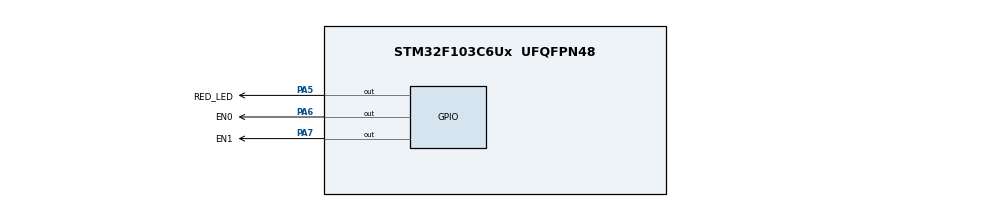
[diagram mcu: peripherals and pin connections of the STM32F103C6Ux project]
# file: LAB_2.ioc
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Mcu.Family=STM32F1
Mcu.Name=STM32F103C6Ux
Mcu.Package=UFQFPN48
NVIC.PriorityGroup=NVIC_PRIORITYGROUP_4
NVIC.TIM2_IRQn=true\:0\:0\:false\:false\:true\:true\:true
PA5.GPIO_Label=RED_LED
PA5.Signal=GPIO_Output
PA6.GPIO_Label=EN0
PA6.Signal=GPIO_Output
PA7.GPIO_Label=EN1
PA7.Signal=GPIO_Output
ProjectManager.HeapSize=0x200
ProjectManager.StackSize=0x400
ProjectManager.TargetToolchain=STM32CubeIDE
RCC.APB1Freq_Value=8000000
RCC.APB2Freq_Value=8000000
TIM2.Period=9
TIM2.Prescaler=7999
VP_SYS_VS_ND.Mode=No_Debug
VP_TIM2_VS_ClockSourceINT.Mode=Internal
board=custom

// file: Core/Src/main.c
/* USER CODE BEGIN Header */
/**
  ******************************************************************************
  * @file           : main.c
  * @brief          : Main program body
  ******************************************************************************
  * @attention
  *
  * <h2><center>&copy; Copyright (c) 2025 STMicroelectronics.
  * All rights reserved.</center></h2>
  *
  * This software component is licensed by ST under BSD 3-Clause license,
  * the "License"; You may not use this file except in compliance with the
  * License. You may obtain a copy of the License at:
  *                        opensource.org/licenses/BSD-3-Clause
  *
  ******************************************************************************
  */
/* USER CODE END Header */
#include "main.h"

/* USER CODE BEGIN Includes */
#include "software_timer.h"
/* USER CODE END Includes */

TIM_HandleTypeDef htim2;

void SystemClock_Config(void);
static void MX_GPIO_Init(void);
static void MX_TIM2_Init(void);

void display7SEG(int num){
	switch(num){
	case 0:
		HAL_GPIO_WritePin(GPIOB, SEG_a, GPIO_PIN_RESET);
		HAL_GPIO_WritePin(GPIOB, SEG_b, GPIO_PIN_RESET);
		HAL_GPIO_WritePin(GPIOB, SEG_c, GPIO_PIN_RESET);
		HAL_GPIO_WritePin(GPIOB, SEG_d, GPIO_PIN_RESET);
		HAL_GPIO_WritePin(GPIOB, SEG_e, GPIO_PIN_RESET);
		HAL_GPIO_WritePin(GPIOB, SEG_f, GPIO_PIN_RESET);
		HAL_GPIO_WritePin(GPIOB, SEG_g, GPIO_PIN_SET);
		break;
	case 1:
		HAL_GPIO_WritePin(GPIOB, SEG_a, GPIO_PIN_SET);
		HAL_GPIO_WritePin(GPIOB, SEG_b, GPIO_PIN_RESET);
		HAL_GPIO_WritePin(GPIOB, SEG_c, GPIO_PIN_RESET);
		HAL_GPIO_WritePin(GPIOB, SEG_d, GPIO_PIN_SET);
		HAL_GPIO_WritePin(GPIOB, SEG_e, GPIO_PIN_SET);
		HAL_GPIO_WritePin(GPIOB, SEG_f, GPIO_PIN_SET);
		HAL_GPIO_WritePin(GPIOB, SEG_g, GPIO_PIN_SET);
		break;
	case 2:
		HAL_GPIO_WritePin(GPIOB, SEG_a, GPIO_PIN_RESET);
		HAL_GPIO_WritePin(GPIOB, SEG_b, GPIO_PIN_RESET);
		HAL_GPIO_WritePin(GPIOB, SEG_c, GPIO_PIN_SET);
		HAL_GPIO_WritePin(GPIOB, SEG_d, GPIO_PIN_RESET);
		HAL_GPIO_WritePin(GPIOB, SEG_e, GPIO_PIN_RESET);
		HAL_GPIO_WritePin(GPIOB, SEG_f, GPIO_PIN_SET);
		HAL_GPIO_WritePin(GPIOB, SEG_g, GPIO_PIN_RESET);
		break;
	case 3:
		HAL_GPIO_WritePin(GPIOB, SEG_a, GPIO_PIN_RESET);
		HAL_GPIO_WritePin(GPIOB, SEG_b, GPIO_PIN_RESET);
		HAL_GPIO_WritePin(GPIOB, SEG_c, GPIO_PIN_RESET);
		HAL_GPIO_WritePin(GPIOB, SEG_d, GPIO_PIN_RESET);
		HAL_GPIO_WritePin(GPIOB, SEG_e, GPIO_PIN_SET);
		HAL_GPIO_WritePin(GPIOB, SEG_f, GPIO_PIN_SET);
		HAL_GPIO_WritePin(GPIOB, SEG_g, GPIO_PIN_RESET);
		break;
	case 4:
		HAL_GPIO_WritePin(GPIOB, SEG_a, GPIO_PIN_SET);
		HAL_GPIO_WritePin(GPIOB, SEG_b, GPIO_PIN_RESET);
		HAL_GPIO_WritePin(GPIOB, SEG_c, GPIO_PIN_RESET);
		HAL_GPIO_WritePin(GPIOB, SEG_d, GPIO_PIN_SET);
		HAL_GPIO_WritePin(GPIOB, SEG_e, GPIO_PIN_SET);
		HAL_GPIO_WritePin(GPIOB, SEG_f, GPIO_PIN_RESET);
		HAL_GPIO_WritePin(GPIOB, SEG_g, GPIO_PIN_RESET);
		break;
	case 5:
		HAL_GPIO_WritePin(GPIOB, SEG_a, GPIO_PIN_RESET);
		HAL_GPIO_WritePin(GPIOB, SEG_b, GPIO_PIN_SET);
		HAL_GPIO_WritePin(GPIOB, SEG_c, GPIO_PIN_RESET);
		HAL_GPIO_WritePin(GPIOB, SEG_d, GPIO_PIN_RESET);
		HAL_GPIO_WritePin(GPIOB, SEG_e, GPIO_PIN_SET);
		HAL_GPIO_WritePin(GPIOB, SEG_f, GPIO_PIN_RESET);
		HAL_GPIO_WritePin(GPIOB, SEG_g, GPIO_PIN_RESET);
		break;
	case 6:
		HAL_GPIO_WritePin(GPIOB, SEG_a, GPIO_PIN_RESET);
		HAL_GPIO_WritePin(GPIOB, SEG_b, GPIO_PIN_SET);
		HAL_GPIO_WritePin(GPIOB, SEG_c, GPIO_PIN_RESET);
		HAL_GPIO_WritePin(GPIOB, SEG_d, GPIO_PIN_RESET);
		HAL_GPIO_WritePin(GPIOB, SEG_e, GPIO_PIN_RESET);
		HAL_GPIO_WritePin(GPIOB, SEG_f, GPIO_PIN_RESET);
		HAL_GPIO_WritePin(GPIOB, SEG_g, GPIO_PIN_RESET);
		break;
	case 7:
		HAL_GPIO_WritePin(GPIOB, SEG_a, GPIO_PIN_RESET);
		HAL_GPIO_WritePin(GPIOB, SEG_b, GPIO_PIN_RESET);
		HAL_GPIO_WritePin(GPIOB, SEG_c, GPIO_PIN_RESET);
		HAL_GPIO_WritePin(GPIOB, SEG_d, GPIO_PIN_SET);
		HAL_GPIO_WritePin(GPIOB, SEG_e, GPIO_PIN_SET);
		HAL_GPIO_WritePin(GPIOB, SEG_f, GPIO_PIN_SET);
		HAL_GPIO_WritePin(GPIOB, SEG_g, GPIO_PIN_SET);
		break;
	case 8:
		HAL_GPIO_WritePin(GPIOB, SEG_a, GPIO_PIN_RESET);
		HAL_GPIO_WritePin(GPIOB, SEG_b, GPIO_PIN_RESET);
		HAL_GPIO_WritePin(GPIOB, SEG_c, GPIO_PIN_RESET);
		HAL_GPIO_WritePin(GPIOB, SEG_d, GPIO_PIN_RESET);
		HAL_GPIO_WritePin(GPIOB, SEG_e, GPIO_PIN_RESET);
		HAL_GPIO_WritePin(GPIOB, SEG_f, GPIO_PIN_RESET);
		HAL_GPIO_WritePin(GPIOB, SEG_g, GPIO_PIN_RESET);
		break;
	case 9:
		HAL_GPIO_WritePin(GPIOB, SEG_a, GPIO_PIN_RESET);
		HAL_GPIO_WritePin(GPIOB, SEG_b, GPIO_PIN_RESET);
		HAL_GPIO_WritePin(GPIOB, SEG_c, GPIO_PIN_RESET);
		HAL_GPIO_WritePin(GPIOB, SEG_d, GPIO_PIN_RESET);
		HAL_GPIO_WritePin(GPIOB, SEG_e, GPIO_PIN_SET);
		HAL_GPIO_WritePin(GPIOB, SEG_f, GPIO_PIN_RESET);
		HAL_GPIO_WritePin(GPIOB, SEG_g, GPIO_PIN_RESET);
		break;

	}
}
const int MAX_LED = 4;
int index_led = 0;
int led_buffer[4] = {1, 2, 3, 4};
int hour = 15, minute = 8, second = 50;
void update7SEG(int index){
    switch (index){
        case 0:
        	HAL_GPIO_WritePin(GPIOA, EN1| EN2| EN3, 1);
            HAL_GPIO_WritePin(GPIOA, EN0, 0);
            display7SEG(led_buffer[0]);
            break;
        case 1:
        	HAL_GPIO_WritePin(GPIOA, EN0| EN2| EN3, 1);
        	HAL_GPIO_WritePin(GPIOA, EN1, 0);
			display7SEG(led_buffer[1]);
            break;
        case 2:
        	HAL_GPIO_WritePin(GPIOA, EN0| EN1| EN3, 1);
        	HAL_GPIO_WritePin(GPIOA, EN2, 0);
			display7SEG(led_buffer[2]);
            break;
        case 3:
        	HAL_GPIO_WritePin(GPIOA, EN0| EN1| EN2, 1);
        	HAL_GPIO_WritePin(GPIOA, EN3, 0);
			display7SEG(led_buffer[3]);
            break;
        default:
            break;
    }
}
// ROW =1; COL = 0;
void updateClockBuffer(){
	led_buffer[0] = hour / 10;
	led_buffer[1] = hour % 10;
	led_buffer[2] = minute / 60;
	led_buffer[3] = minute % 60;
}
void displayMatricsSEG(int index){
	HAL_GPIO_WritePin(GPIOA, ENM0, (index >> 0) & 1);
	HAL_GPIO_WritePin(GPIOA, ENM1, (index >> 1) & 1);
	HAL_GPIO_WritePin(GPIOA, ENM2, (index >> 2) & 1);
	HAL_GPIO_WritePin(GPIOA, ENM3, (index >> 3) & 1);
	HAL_GPIO_WritePin(GPIOA, ENM4, (index >> 4) & 1);
	HAL_GPIO_WritePin(GPIOA, ENM5, (index >> 5) & 1);
	HAL_GPIO_WritePin(GPIOA, ENM6, (index >> 6) & 1);
	HAL_GPIO_WritePin(GPIOA, ENM7, (index >> 7) & 1);
}
const int MAX_LED_MATRIX = 8;
 int index_led_matrix = 0;
 uint8_t matrix_buffer[8] = {0xE7, 0b11011011,
		 	 	 	 	 	 	   0b10111101,
								   0b10111101,
								   0b10000001,
								   0b10111101,
								   0b10111101,
								   0b10111101};
 void updateLEDMatrix(int index){
	 switch(index){
	 case 0:
		 HAL_GPIO_WritePin(GPIOB, ROW0, 0);
		 HAL_GPIO_WritePin(GPIOB, ROW1| ROW2| ROW3| ROW4 | ROW5| ROW6| ROW7, 1);
		 displayMatricsSEG(matrix_buffer[0]);
		 break;
	 case 1:
		 HAL_GPIO_WritePin(GPIOB, ROW1, 0);
		 HAL_GPIO_WritePin(GPIOB, ROW0| ROW2| ROW3| ROW4 | ROW5| ROW6| ROW7, 1);
		 displayMatricsSEG(matrix_buffer[1]);
		 break;
	 case 2:
		 HAL_GPIO_WritePin(GPIOB, ROW2, 0);
		 HAL_GPIO_WritePin(GPIOB, ROW1| ROW0| ROW3| ROW4 | ROW5| ROW6| ROW7, 1);
		 displayMatricsSEG(matrix_buffer[2]);
		 break;
	 case 3:
		 HAL_GPIO_WritePin(GPIOB, ROW3, 0);
		 HAL_GPIO_WritePin(GPIOB, ROW1| ROW2| ROW0| ROW4 | ROW5| ROW6| ROW7, 1);
		 displayMatricsSEG(matrix_buffer[3]);
		 break;
	 case 4:
		 HAL_GPIO_WritePin(GPIOB, ROW4, 0);
		 HAL_GPIO_WritePin(GPIOB, ROW1| ROW2| ROW3| ROW0 | ROW5| ROW6| ROW7, 1);
		 displayMatricsSEG(matrix_buffer[4]);
		 break;
	 case 5:
		 HAL_GPIO_WritePin(GPIOB, ROW5, 0);
		 HAL_GPIO_WritePin(GPIOB, ROW1| ROW2| ROW3| ROW4 | ROW0| ROW6| ROW7, 1);
		 displayMatricsSEG(matrix_buffer[5]);
		 break;
	 case 6:
		 HAL_GPIO_WritePin(GPIOB, ROW6, 0);
		 HAL_GPIO_WritePin(GPIOB, ROW1| ROW2| ROW3| ROW4 | ROW5| ROW0| ROW7, 1);
		 displayMatricsSEG(matrix_buffer[6]);
		 break;
	 case 7:
		 HAL_GPIO_WritePin(GPIOB, ROW7, 0);
		 HAL_GPIO_WritePin(GPIOB, ROW1| ROW2| ROW3| ROW4 | ROW5| ROW6| ROW0, 1);
		 displayMatricsSEG(matrix_buffer[7]);
		 break;
	 }
 }
 void updateMatricBuffer(){
	 for(int i = 0; i < MAX_LED_MATRIX; ++i){
		 matrix_buffer[i] = matrix_buffer[i] << 1 | matrix_buffer[i] >> 7;
	 }
 }

int main(void)
{

  /* MCU Configuration--------------------------------------------------------*/

  /* Reset of all peripherals, Initializes the Flash interface and the Systick. */
  HAL_Init();

  /* Configure the system clock */
  SystemClock_Config();

  /* Initialize all configured peripherals */
  MX_GPIO_Init();
  MX_TIM2_Init();
  /* USER CODE BEGIN 2 */
  HAL_TIM_Base_Start_IT(&htim2);

  /* USER CODE END 2 */

  /* Infinite loop */
  /* USER CODE BEGIN WHILE */
  setTimer1(100, 0);
  setTimer1(25, 1);
  setTimer1(100, 2);
  setTimer1(300, 3);
  while (1)
  {

	  if(isTimerExpried(0) == 1){
		  setTimer1(100, 0);
		  HAL_GPIO_TogglePin(GPIOA, RED_LED_Pin);
		  HAL_GPIO_TogglePin(GPIOA, DOT);
		  ++second;
		  if (second >= 60) {
		 	second = 0;
		 	++minute;
		 }

		 		  if (minute >= 60) {
		 			  minute = 0;
		 			  ++hour;
		 		  }
		 		  	  if (hour >= 24) {
		 			  hour = 0;
		 		  }
		 		  updateClockBuffer();
	  }

	  if (isTimerExpried(1) == 1) {
		  setTimer1(25,1);
		  update7SEG(index_led);
		  ++index_led;
		  if (index_led > 3) {
			  index_led = 0;
		  }
	  }
      if (isTimerExpried(2) == 1) {
    	  setTimer1(1, 2);
    	  updateLEDMatrix(index_led_matrix);
    	  ++index_led_matrix;
    	  if (index_led_matrix >= MAX_LED_MATRIX) {
    		  index_led_matrix = 0;
    	  }
      }

	  if (isTimerExpried(3) == 1) {
		  setTimer1(200,3);
    	  updateMatricBuffer();
	  }

    /* USER CODE END WHILE */

  }
}

void SystemClock_Config(void)
{
  RCC_OscInitTypeDef RCC_OscInitStruct = {0};
  RCC_ClkInitTypeDef RCC_ClkInitStruct = {0};

  /** Initializes the RCC Oscillators according to the specified parameters
  * in the RCC_OscInitTypeDef structure.
  */
  RCC_OscInitStruct.OscillatorType = RCC_OSCILLATORTYPE_HSI;
  RCC_OscInitStruct.HSIState = RCC_HSI_ON;
  RCC_OscInitStruct.HSICalibrationValue = RCC_HSICALIBRATION_DEFAULT;
  RCC_OscInitStruct.PLL.PLLState = RCC_PLL_NONE;
  if (HAL_RCC_OscConfig(&RCC_OscInitStruct) != HAL_OK)
  {
    Error_Handler();
  }
  /** Initializes the CPU, AHB and APB buses clocks
  */
  RCC_ClkInitStruct.ClockType = RCC_CLOCKTYPE_HCLK|RCC_CLOCKTYPE_SYSCLK
                              |RCC_CLOCKTYPE_PCLK1|RCC_CLOCKTYPE_PCLK2;
  RCC_ClkInitStruct.SYSCLKSource = RCC_SYSCLKSOURCE_HSI;
  RCC_ClkInitStruct.AHBCLKDivider = RCC_SYSCLK_DIV1;
  RCC_ClkInitStruct.APB1CLKDivider = RCC_HCLK_DIV1;
  RCC_ClkInitStruct.APB2CLKDivider = RCC_HCLK_DIV1;

  if (HAL_RCC_ClockConfig(&RCC_ClkInitStruct, FLASH_LATENCY_0) != HAL_OK)
  {
    Error_Handler();
  }
}

static void MX_TIM2_Init(void)
{

  TIM_ClockConfigTypeDef sClockSourceConfig = {0};
  TIM_MasterConfigTypeDef sMasterConfig = {0};

  htim2.Instance = TIM2;
  htim2.Init.Prescaler = 7999;
  htim2.Init.CounterMode = TIM_COUNTERMODE_UP;
  htim2.Init.Period = 9;
  htim2.Init.ClockDivision = TIM_CLOCKDIVISION_DIV1;
  htim2.Init.AutoReloadPreload = TIM_AUTORELOAD_PRELOAD_DISABLE;
  if (HAL_TIM_Base_Init(&htim2) != HAL_OK)
  {
    Error_Handler();
  }
  sClockSourceConfig.ClockSource = TIM_CLOCKSOURCE_INTERNAL;
  if (HAL_TIM_ConfigClockSource(&htim2, &sClockSourceConfig) != HAL_OK)
  {
    Error_Handler();
  }
  sMasterConfig.MasterOutputTrigger = TIM_TRGO_RESET;
  sMasterConfig.MasterSlaveMode = TIM_MASTERSLAVEMODE_DISABLE;
  if (HAL_TIMEx_MasterConfigSynchronization(&htim2, &sMasterConfig) != HAL_OK)
  {
    Error_Handler();
  }

}

static void MX_GPIO_Init(void)
{
  GPIO_InitTypeDef GPIO_InitStruct = {0};

  /* GPIO Ports Clock Enable */
  __HAL_RCC_GPIOA_CLK_ENABLE();
  __HAL_RCC_GPIOB_CLK_ENABLE();

  /*Configure GPIO pin Output Level */
  HAL_GPIO_WritePin(GPIOA, RED_LED_Pin|EN0|EN1|EN2|EN3|DOT|ENM0|ENM1|ENM2|ENM3|ENM4|ENM5|ENM6|ENM7, GPIO_PIN_RESET);

  /*Configure GPIO pin Output Level */
   HAL_GPIO_WritePin(GPIOB, SEG_a|SEG_b|SEG_c|SEG_d
                           |SEG_e|SEG_f|SEG_g|ROW0|ROW1|ROW2|ROW3|ROW4|ROW5|ROW6|ROW7, GPIO_PIN_RESET);

  /*Configure GPIO pins : RED_LED_Pin EN0_Pin EN1_Pin */
  GPIO_InitStruct.Pin = RED_LED_Pin|EN0|EN1|EN2|EN3|DOT|ENM0|ENM1|ENM2|ENM3|ENM4|ENM5|ENM6|ENM7;
  GPIO_InitStruct.Mode = GPIO_MODE_OUTPUT_PP;
  GPIO_InitStruct.Pull = GPIO_NOPULL;
  GPIO_InitStruct.Speed = GPIO_SPEED_FREQ_LOW;
  HAL_GPIO_Init(GPIOA, &GPIO_InitStruct);

  /*Configure GPIO pins : SEG0_Pin SEG1_Pin SEG2_Pin SEG3_Pin
                           SEG4_Pin SEG5_Pin SEG6_Pin */
  GPIO_InitStruct.Pin =  SEG_a|SEG_b|SEG_c|SEG_d
          	  	  	  	  |SEG_e|SEG_f|SEG_g|ROW0|ROW1|ROW2|ROW3|ROW4|ROW5|ROW6|ROW7;
  GPIO_InitStruct.Mode = GPIO_MODE_OUTPUT_PP;
  GPIO_InitStruct.Pull = GPIO_NOPULL;
  GPIO_InitStruct.Speed = GPIO_SPEED_FREQ_LOW;
  HAL_GPIO_Init(GPIOB, &GPIO_InitStruct);

}

/* USER CODE BEGIN 4 */
void HAL_TIM_PeriodElapsedCallback(TIM_HandleTypeDef *htim){
timerRun();
}
/* USER CODE END 4 */

void Error_Handler(void)
{
  __disable_irq();
  while (1)
  {
  }
}

/************************ (C) COPYRIGHT STMicroelectronics *****END OF FILE****/
